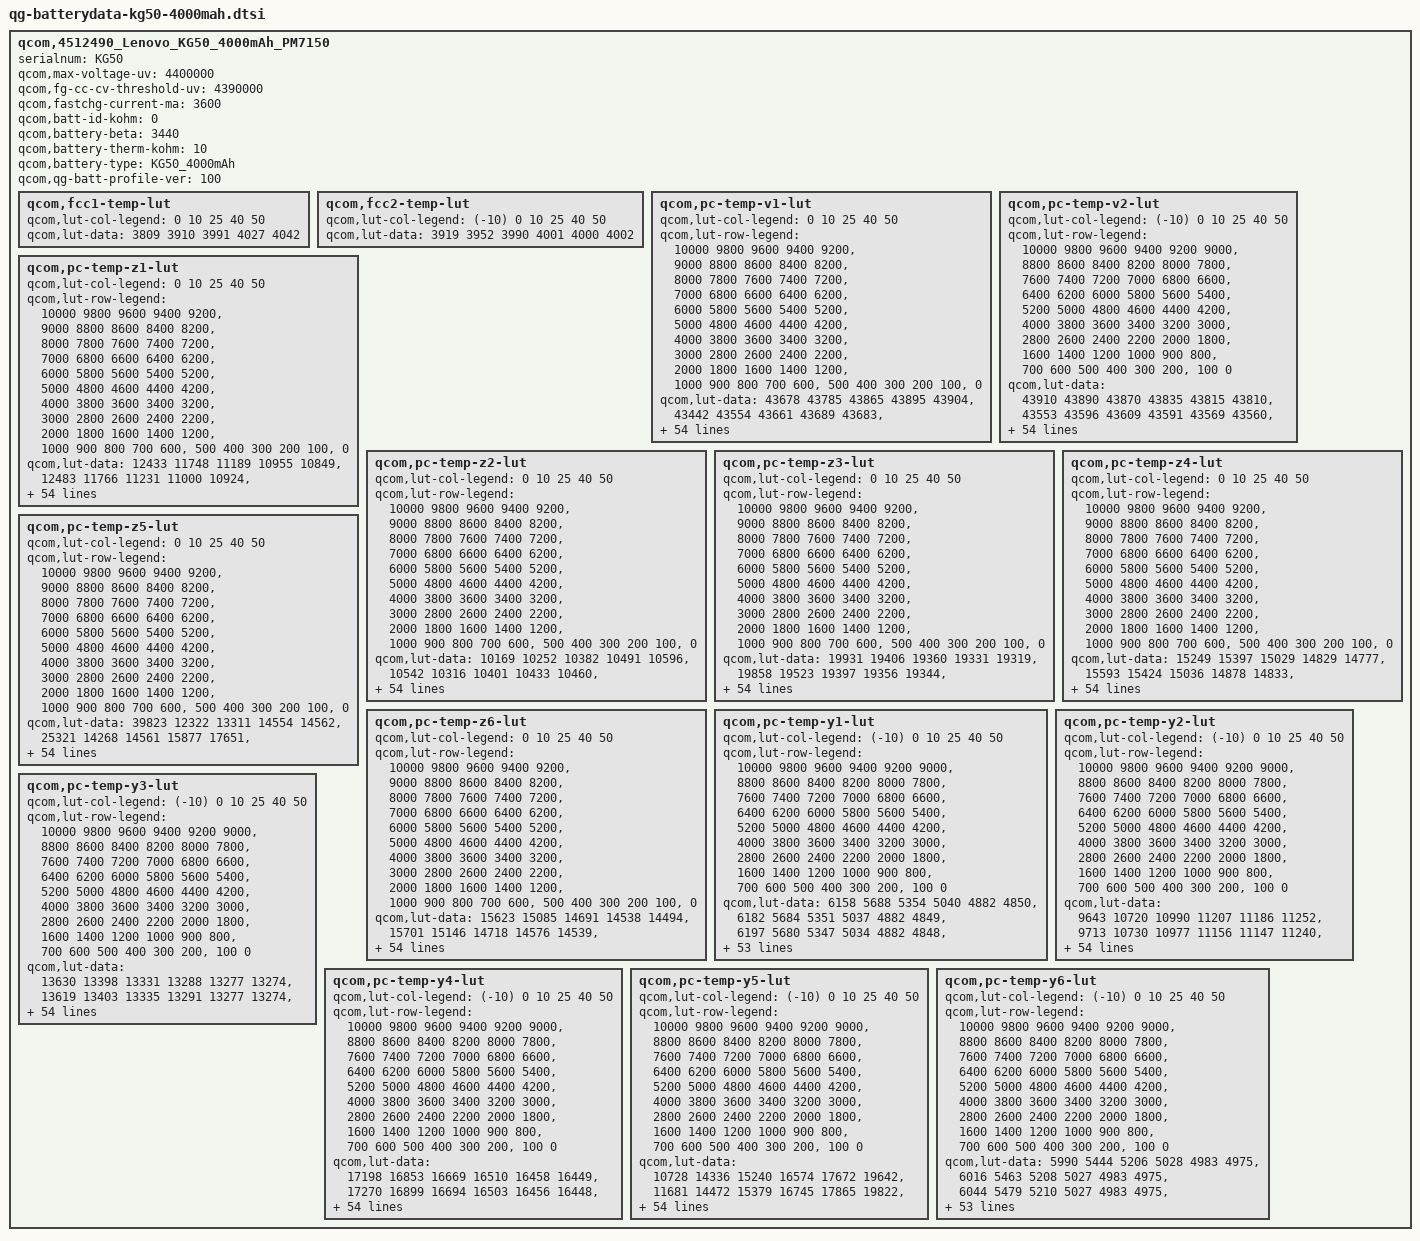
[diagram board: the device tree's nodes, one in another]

qcom,4512490_Lenovo_KG50_4000mAh_PM7150 {
    /* 4512490_Lenovo_KG50_4000mAh_PM7150_averaged_MasterSlave_Mar26th2020 */
    serialnum = "KG50";
    qcom,max-voltage-uv = <4400000>;
    qcom,fg-cc-cv-threshold-uv = <4390000>;
    qcom,fastchg-current-ma = <3600>;
    qcom,batt-id-kohm = <0>;
    qcom,battery-beta = <3440>;
    qcom,battery-therm-kohm = <10>;
    qcom,battery-type = "KG50_4000mAh";
    qcom,qg-batt-profile-ver = <100>;

	qcom,fcc1-temp-lut {
		qcom,lut-col-legend = <0 10 25 40 50>;
		qcom,lut-data = <3809 3910 3991 4027 4042>;
	};

	qcom,fcc2-temp-lut {
		qcom,lut-col-legend = <(-10) 0 10 25 40 50>;
		qcom,lut-data = <3919 3952 3990 4001 4000 4002>;
	};

	qcom,pc-temp-v1-lut {
		qcom,lut-col-legend = <0 10 25 40 50>;
		qcom,lut-row-legend = <10000 9800 9600 9400 9200>,
			<9000 8800 8600 8400 8200>,
			<8000 7800 7600 7400 7200>,
			<7000 6800 6600 6400 6200>,
			<6000 5800 5600 5400 5200>,
			<5000 4800 4600 4400 4200>,
			<4000 3800 3600 3400 3200>,
			<3000 2800 2600 2400 2200>,
			<2000 1800 1600 1400 1200>,
			<1000 900 800 700 600>,
			<500 400 300 200 100>,
			<0>;
		qcom,lut-data = <43678 43785 43865 43895 43904>,
			<43442 43554 43661 43689 43683>,
			<43193 43324 43433 43471 43469>,
			<42948 43096 43204 43249 43252>,
			<42714 42865 42974 43023 43029>,
			<42484 42630 42740 42792 42802>,
			<42256 42394 42506 42561 42574>,
			<42031 42163 42272 42327 42344>,
			<41810 41935 42042 42097 42114>,
			<41592 41712 41813 41867 41883>,
			<41377 41493 41587 41640 41654>,
			<41171 41279 41367 41417 41431>,
			<40973 41072 41153 41198 41211>,
			<40780 40875 40947 40988 41000>,
			<40588 40684 40747 40785 40795>,
			<40399 40494 40554 40590 40599>,
			<40220 40307 40368 40401 40409>,
			<40055 40132 40189 40218 40226>,
			<39898 39976 40025 40045 40051>,
			<39749 39823 39878 39891 39892>,
			<39607 39656 39709 39728 39730>,
			<39460 39481 39463 39513 39525>,
			<39297 39294 39198 39262 39279>,
			<39126 39061 39023 39065 39075>,
			<38962 38838 38900 38925 38924>,
			<38784 38716 38793 38804 38797>,
			<38627 38643 38692 38689 38682>,
			<38536 38578 38600 38585 38579>,
			<38474 38507 38512 38492 38485>,
			<38423 38438 38426 38406 38394>,
			<38376 38376 38352 38328 38311>,
			<38335 38317 38287 38256 38237>,
			<38297 38264 38230 38191 38169>,
			<38261 38218 38178 38130 38104>,
			<38228 38176 38133 38076 38043>,
			<38197 38138 38089 38023 37982>,
			<38168 38106 38046 37970 37918>,
			<38130 38068 38002 37915 37850>,
			<38074 38005 37938 37846 37772>,
			<37999 37910 37846 37754 37678>,
			<37906 37804 37739 37648 37572>,
			<37782 37680 37617 37525 37444>,
			<37637 37538 37478 37384 37300>,
			<37469 37370 37315 37225 37142>,
			<37317 37226 37175 37093 37023>,
			<37212 37132 37086 37013 36949>,
			<37178 37105 37061 36991 36926>,
			<37153 37082 37043 36975 36911>,
			<37120 37057 37022 36955 36892>,
			<37076 37002 36969 36878 36785>,
			<36959 36759 36705 36574 36457>,
			<36592 36311 36268 36122 36001>,
			<36067 35721 35691 35535 35406>,
			<35366 34913 34909 34732 34589>,
			<34267 33618 33708 33487 33312>,
			<30000 30000 30000 30000 30000>;
	};

	qcom,pc-temp-v2-lut {
		qcom,lut-col-legend = <(-10) 0 10 25 40 50>;
		qcom,lut-row-legend = <10000 9800 9600 9400 9200 9000>,
			<8800 8600 8400 8200 8000 7800>,
			<7600 7400 7200 7000 6800 6600>,
			<6400 6200 6000 5800 5600 5400>,
			<5200 5000 4800 4600 4400 4200>,
			<4000 3800 3600 3400 3200 3000>,
			<2800 2600 2400 2200 2000 1800>,
			<1600 1400 1200 1000 900 800>,
			<700 600 500 400 300 200>,
			<100 0>;
		qcom,lut-data = <43910 43890 43870 43835 43815 43810>,
			<43553 43596 43609 43591 43569 43560>,
			<43233 43319 43354 43350 43328 43316>,
			<42956 43059 43109 43114 43091 43079>,
			<42720 42819 42873 42884 42862 42851>,
			<42492 42581 42637 42653 42632 42622>,
			<42258 42338 42398 42417 42398 42389>,
			<42024 42096 42160 42180 42163 42154>,
			<41778 41861 41926 41948 41932 41924>,
			<41505 41636 41696 41720 41703 41695>,
			<41255 41413 41469 41494 41477 41469>,
			<41077 41191 41247 41274 41258 41249>,
			<40935 40970 41029 41056 41042 41032>,
			<40753 40767 40821 40848 40835 40825>,
			<40487 40582 40619 40645 40632 40621>,
			<40195 40396 40424 40449 40436 40426>,
			<39943 40191 40241 40258 40247 40239>,
			<39710 39977 40061 40073 40066 40058>,
			<39489 39760 39859 39896 39894 39887>,
			<39279 39534 39631 39729 39735 39729>,
			<39076 39313 39407 39548 39560 39555>,
			<38864 39109 39198 39316 39331 39329>,
			<38635 38918 39002 39072 39088 39090>,
			<38450 38744 38833 38887 38901 38905>,
			<38327 38583 38685 38738 38751 38755>,
			<38231 38435 38554 38609 38622 38626>,
			<38163 38296 38437 38494 38510 38512>,
			<38109 38165 38331 38393 38410 38410>,
			<38058 38067 38232 38299 38318 38316>,
			<38006 38002 38137 38213 38233 38228>,
			<37954 37950 38049 38134 38154 38149>,
			<37900 37902 37965 38060 38084 38078>,
			<37846 37859 37890 37991 38017 38011>,
			<37788 37814 37834 37926 37949 37938>,
			<37730 37769 37795 37867 37879 37858>,
			<37670 37722 37755 37803 37801 37769>,
			<37606 37674 37710 37732 37708 37662>,
			<37537 37626 37660 37655 37607 37548>,
			<37462 37566 37597 37575 37516 37451>,
			<37377 37488 37519 37493 37432 37366>,
			<37281 37393 37425 37402 37342 37276>,
			<37183 37281 37306 37293 37235 37171>,
			<37085 37146 37166 37167 37113 37049>,
			<36994 37002 37010 37010 36960 36897>,
			<36920 36860 36882 36908 36868 36812>,
			<36848 36758 36802 36867 36835 36781>,
			<36812 36720 36767 36851 36821 36769>,
			<36770 36681 36730 36832 36806 36753>,
			<36715 36636 36677 36794 36772 36703>,
			<36647 36572 36567 36681 36629 36503>,
			<36539 36438 36300 36356 36261 36093>,
			<36325 36127 35803 35847 35739 35549>,
			<35951 35604 35139 35195 35065 34837>,
			<35375 34883 34255 34302 34151 33894>,
			<34487 33798 32912 33056 32824 32377>,
			<33082 32024 29815 30325 30858 29304>;
	};

	qcom,pc-temp-z1-lut {
		qcom,lut-col-legend = <0 10 25 40 50>;
		qcom,lut-row-legend = <10000 9800 9600 9400 9200>,
			<9000 8800 8600 8400 8200>,
			<8000 7800 7600 7400 7200>,
			<7000 6800 6600 6400 6200>,
			<6000 5800 5600 5400 5200>,
			<5000 4800 4600 4400 4200>,
			<4000 3800 3600 3400 3200>,
			<3000 2800 2600 2400 2200>,
			<2000 1800 1600 1400 1200>,
			<1000 900 800 700 600>,
			<500 400 300 200 100>,
			<0>;
		qcom,lut-data = <12433 11748 11189 10955 10849>,
			<12483 11766 11231 11000 10924>,
			<12500 11782 11252 11010 10941>,
			<12501 11796 11252 11013 10948>,
			<12490 11801 11244 11012 10950>,
			<12475 11795 11236 11009 10952>,
			<12463 11782 11230 11008 10952>,
			<12453 11765 11226 11007 10953>,
			<12440 11740 11224 11006 10953>,
			<12422 11723 11222 11004 10952>,
			<12398 11721 11220 11003 10951>,
			<12380 11724 11217 11002 10951>,
			<12370 11724 11214 11002 10951>,
			<12359 11717 11214 11002 10951>,
			<12340 11710 11215 11002 10951>,
			<12316 11705 11216 11003 10951>,
			<12307 11702 11216 11003 10951>,
			<12316 11702 11216 11003 10952>,
			<12333 11712 11217 11004 10953>,
			<12346 11724 11221 11005 10954>,
			<12355 11723 11223 11006 10955>,
			<12360 11716 11224 11007 10955>,
			<12354 11713 11225 11007 10956>,
			<12345 11718 11227 11008 10957>,
			<12342 11726 11230 11010 10958>,
			<12353 11732 11234 11013 10961>,
			<12366 11736 11238 11015 10963>,
			<12365 11738 11243 11018 10965>,
			<12359 11736 11247 11021 10967>,
			<12356 11731 11252 11023 10969>,
			<12368 11731 11256 11026 10971>,
			<12392 11738 11261 11029 10973>,
			<12405 11747 11265 11032 10975>,
			<12403 11753 11270 11036 10977>,
			<12398 11759 11274 11039 10980>,
			<12399 11767 11278 11042 10982>,
			<12409 11782 11284 11046 10985>,
			<12421 11795 11291 11049 10987>,
			<12438 11802 11296 11052 10989>,
			<12456 11807 11301 11055 10991>,
			<12464 11812 11304 11058 10993>,
			<12462 11825 11305 11060 10995>,
			<12469 11831 11305 11061 10997>,
			<12494 11819 11313 11063 10997>,
			<12470 11808 11316 11066 10998>,
			<12506 11837 11320 11067 10999>,
			<12484 11821 11324 11066 10999>,
			<12485 11821 11325 11068 11000>,
			<12504 11820 11333 11069 11001>,
			<12504 11844 11334 11073 11003>,
			<12485 11861 11336 11077 11007>,
			<12505 11874 11349 11082 11011>,
			<12554 11889 11358 11090 11018>,
			<12520 11902 11382 11101 11026>,
			<12520 11902 11382 11101 11026>,
			<12520 11902 11382 11101 11026>;
	};

	qcom,pc-temp-z2-lut {
		qcom,lut-col-legend = <0 10 25 40 50>;
		qcom,lut-row-legend = <10000 9800 9600 9400 9200>,
			<9000 8800 8600 8400 8200>,
			<8000 7800 7600 7400 7200>,
			<7000 6800 6600 6400 6200>,
			<6000 5800 5600 5400 5200>,
			<5000 4800 4600 4400 4200>,
			<4000 3800 3600 3400 3200>,
			<3000 2800 2600 2400 2200>,
			<2000 1800 1600 1400 1200>,
			<1000 900 800 700 600>,
			<500 400 300 200 100>,
			<0>;
		qcom,lut-data = <10169 10252 10382 10491 10596>,
			<10542 10316 10401 10433 10460>,
			<10289 10298 10420 10430 10500>,
			<10114 10263 10411 10428 10511>,
			<10098 10231 10372 10423 10496>,
			<10087 10205 10332 10418 10472>,
			<10079 10182 10299 10408 10435>,
			<10072 10163 10274 10383 10379>,
			<10066 10144 10273 10357 10354>,
			<10059 10134 10288 10332 10351>,
			<10049 10141 10303 10315 10351>,
			<10041 10160 10313 10317 10358>,
			<10033 10189 10322 10327 10389>,
			<10028 10331 10329 10333 10416>,
			<10032 10491 10338 10337 10426>,
			<10044 10477 10347 10344 10434>,
			<10053 10330 10355 10351 10442>,
			<10058 10250 10364 10356 10456>,
			<10064 10263 10375 10365 10474>,
			<10072 10280 10392 10393 10497>,
			<10087 10298 10419 10437 10528>,
			<10104 10318 10505 10517 10604>,
			<10121 10331 10604 10630 10728>,
			<10137 10338 10596 10681 10774>,
			<10150 10343 10485 10671 10772>,
			<10165 10339 10416 10658 10760>,
			<10178 10317 10453 10629 10693>,
			<10179 10301 10508 10534 10536>,
			<10175 10306 10513 10478 10447>,
			<10174 10316 10484 10432 10412>,
			<10175 10323 10458 10393 10395>,
			<10177 10326 10447 10376 10404>,
			<10179 10331 10440 10366 10436>,
			<10185 10340 10443 10370 10475>,
			<10192 10352 10471 10412 10531>,
			<10198 10359 10501 10466 10591>,
			<10204 10362 10521 10517 10648>,
			<10212 10364 10539 10572 10701>,
			<10225 10375 10563 10615 10720>,
			<10238 10394 10596 10652 10724>,
			<10242 10403 10614 10675 10728>,
			<10243 10404 10599 10676 10742>,
			<10247 10405 10584 10672 10757>,
			<10267 10410 10589 10684 10715>,
			<10428 10478 10613 10688 10696>,
			<10447 10496 10600 10668 10731>,
			<10398 10488 10569 10673 10722>,
			<10192 10486 10556 10672 10759>,
			<10085 10560 10553 10694 10837>,
			<10094 10627 10569 10712 10786>,
			<9970 10553 10596 10550 10526>,
			<9988 10495 10509 10475 10471>,
			<9883 10357 10464 10398 10408>,
			<9704 10197 10389 10336 10325>,
			<9704 10197 10389 10336 10325>,
			<9704 10197 10389 10336 10325>;
	};

	qcom,pc-temp-z3-lut {
		qcom,lut-col-legend = <0 10 25 40 50>;
		qcom,lut-row-legend = <10000 9800 9600 9400 9200>,
			<9000 8800 8600 8400 8200>,
			<8000 7800 7600 7400 7200>,
			<7000 6800 6600 6400 6200>,
			<6000 5800 5600 5400 5200>,
			<5000 4800 4600 4400 4200>,
			<4000 3800 3600 3400 3200>,
			<3000 2800 2600 2400 2200>,
			<2000 1800 1600 1400 1200>,
			<1000 900 800 700 600>,
			<500 400 300 200 100>,
			<0>;
		qcom,lut-data = <19931 19406 19360 19331 19319>,
			<19858 19523 19397 19356 19344>,
			<19757 19561 19439 19371 19357>,
			<19748 19576 19456 19384 19364>,
			<19763 19585 19465 19392 19370>,
			<19774 19591 19468 19398 19373>,
			<19775 19594 19466 19397 19373>,
			<19770 19594 19461 19391 19366>,
			<19764 19589 19455 19386 19361>,
			<19761 19583 19446 19380 19360>,
			<19759 19573 19440 19376 19359>,
			<19756 19559 19436 19374 19357>,
			<19747 19553 19431 19373 19355>,
			<19737 19558 19427 19371 19353>,
			<19727 19565 19421 19365 19349>,
			<19717 19560 19417 19360 19344>,
			<19707 19543 19415 19357 19341>,
			<19699 19528 19412 19356 19339>,
			<19692 19520 19408 19354 19337>,
			<19686 19514 19402 19351 19334>,
			<19679 19515 19400 19348 19332>,
			<19675 19521 19413 19351 19333>,
			<19680 19526 19430 19361 19340>,
			<19687 19529 19428 19365 19349>,
			<19690 19532 19405 19364 19366>,
			<19693 19530 19391 19363 19382>,
			<19698 19521 19397 19373 19381>,
			<19695 19515 19409 19389 19376>,
			<19687 19517 19421 19393 19371>,
			<19679 19520 19433 19386 19366>,
			<19673 19522 19438 19378 19361>,
			<19667 19524 19434 19372 19354>,
			<19663 19526 19426 19366 19347>,
			<19659 19525 19420 19361 19341>,
			<19656 19522 19415 19356 19334>,
			<19653 19518 19411 19353 19330>,
			<19650 19515 19407 19350 19330>,
			<19647 19511 19404 19348 19331>,
			<19641 19506 19402 19348 19332>,
			<19633 19502 19400 19349 19334>,
			<19624 19497 19399 19351 19336>,
			<19615 19494 19395 19350 19337>,
			<19605 19489 19392 19349 19339>,
			<19594 19482 19388 19350 19342>,
			<19535 19456 19378 19346 19337>,
			<19506 19444 19369 19331 19320>,
			<19452 19435 19366 19327 19318>,
			<19323 19424 19363 19326 19314>,
			<19290 19388 19361 19322 19304>,
			<19284 19383 19351 19324 19317>,
			<19274 19404 19360 19343 19333>,
			<19294 19345 19355 19347 19333>,
			<19298 19354 19360 19347 19335>,
			<19325 19368 19364 19349 19340>,
			<19325 19368 19364 19349 19340>,
			<19325 19368 19364 19349 19340>;
	};

	qcom,pc-temp-z4-lut {
		qcom,lut-col-legend = <0 10 25 40 50>;
		qcom,lut-row-legend = <10000 9800 9600 9400 9200>,
			<9000 8800 8600 8400 8200>,
			<8000 7800 7600 7400 7200>,
			<7000 6800 6600 6400 6200>,
			<6000 5800 5600 5400 5200>,
			<5000 4800 4600 4400 4200>,
			<4000 3800 3600 3400 3200>,
			<3000 2800 2600 2400 2200>,
			<2000 1800 1600 1400 1200>,
			<1000 900 800 700 600>,
			<500 400 300 200 100>,
			<0>;
		qcom,lut-data = <15249 15397 15029 14829 14777>,
			<15593 15424 15036 14878 14833>,
			<15752 15382 14996 14854 14815>,
			<15714 15240 14948 14827 14791>,
			<15559 15105 14889 14798 14767>,
			<15382 15021 14839 14768 14745>,
			<15265 14955 14803 14745 14729>,
			<15175 14904 14775 14727 14717>,
			<15101 14862 14757 14717 14707>,
			<15037 14830 14745 14712 14701>,
			<14983 14807 14735 14708 14695>,
			<14939 14791 14727 14702 14690>,
			<14902 14775 14721 14695 14685>,
			<14871 14748 14716 14689 14680>,
			<14850 14725 14712 14685 14676>,
			<14833 14726 14708 14681 14672>,
			<14822 14744 14703 14676 14668>,
			<14813 14752 14699 14671 14663>,
			<14805 14746 14696 14667 14658>,
			<14797 14740 14693 14663 14654>,
			<14787 14742 14692 14661 14651>,
			<14782 14752 14733 14687 14670>,
			<14790 14769 14800 14753 14732>,
			<14808 14825 14829 14782 14760>,
			<14828 14891 14844 14780 14740>,
			<14868 14899 14849 14773 14714>,
			<14905 14882 14832 14752 14702>,
			<14908 14861 14799 14719 14694>,
			<14899 14842 14773 14705 14688>,
			<14888 14823 14749 14699 14683>,
			<14877 14808 14735 14694 14679>,
			<14864 14796 14732 14689 14674>,
			<14852 14787 14730 14685 14669>,
			<14841 14782 14729 14684 14667>,
			<14831 14779 14728 14683 14666>,
			<14821 14776 14728 14683 14666>,
			<14811 14772 14728 14684 14668>,
			<14802 14769 14730 14688 14674>,
			<14794 14770 14732 14691 14677>,
			<14787 14771 14736 14695 14678>,
			<14779 14771 14739 14697 14678>,
			<14770 14756 14732 14694 14677>,
			<14758 14739 14721 14690 14676>,
			<14739 14726 14714 14687 14675>,
			<14704 14694 14692 14676 14667>,
			<14705 14673 14672 14664 14654>,
			<14756 14669 14663 14656 14645>,
			<14893 14667 14652 14641 14632>,
			<14922 14696 14642 14630 14625>,
			<14917 14696 14647 14633 14629>,
			<14924 14684 14662 14643 14639>,
			<14919 14758 14669 14643 14644>,
			<14931 14757 14665 14646 14645>,
			<14935 14757 14661 14645 14644>,
			<14935 14757 14661 14645 14644>,
			<14935 14757 14661 14645 14644>;
	};

	qcom,pc-temp-z5-lut {
		qcom,lut-col-legend = <0 10 25 40 50>;
		qcom,lut-row-legend = <10000 9800 9600 9400 9200>,
			<9000 8800 8600 8400 8200>,
			<8000 7800 7600 7400 7200>,
			<7000 6800 6600 6400 6200>,
			<6000 5800 5600 5400 5200>,
			<5000 4800 4600 4400 4200>,
			<4000 3800 3600 3400 3200>,
			<3000 2800 2600 2400 2200>,
			<2000 1800 1600 1400 1200>,
			<1000 900 800 700 600>,
			<500 400 300 200 100>,
			<0>;
		qcom,lut-data = <39823 12322 13311 14554 14562>,
			<25321 14268 14561 15877 17651>,
			<15542 15168 16305 17182 19105>,
			<14257 15653 17481 18488 20203>,
			<14695 16165 18337 19678 21425>,
			<15182 16913 19072 20740 22413>,
			<15606 17721 19745 21323 22654>,
			<16029 18457 20217 21780 22532>,
			<16533 19240 20480 21863 22544>,
			<17243 20004 21012 21580 23003>,
			<18081 20609 21405 21435 23746>,
			<18840 21156 21771 21964 24532>,
			<19520 21912 22033 23066 25485>,
			<20258 24913 21969 23491 25934>,
			<21287 28108 22125 23148 25578>,
			<22410 27976 22518 22802 25091>,
			<23085 25625 23108 23181 25293>,
			<23519 24398 23815 24502 26554>,
			<23981 24739 24381 25539 27895>,
			<24728 25306 24830 26116 29221>,
			<26086 27071 25681 26685 30205>,
			<27966 31440 31985 27660 30060>,
			<32258 34092 40246 28810 28807>,
			<37668 34088 39053 28614 27461>,
			<40115 33411 26859 23178 25500>,
			<41967 31784 19247 18260 23915>,
			<43412 27358 19340 19570 23955>,
			<42099 24497 19706 22835 24577>,
			<38225 24796 20926 24244 25287>,
			<35003 25489 24785 24689 26333>,
			<33296 26444 27831 25127 27139>,
			<32005 28589 28943 25806 27152>,
			<31581 30769 29715 26689 27049>,
			<31641 32284 30438 27611 27095>,
			<31870 33593 31163 28821 27854>,
			<32402 34095 31495 29549 28474>,
			<33383 34203 31302 29315 28599>,
			<34317 34203 30869 28675 28978>,
			<35449 34079 30235 28072 29172>,
			<36500 33864 29035 27318 29230>,
			<36353 33684 28080 26686 29330>,
			<34598 33549 27663 26529 30264>,
			<34305 33431 27372 26657 31720>,
			<35810 33017 26651 26697 32321>,
			<34341 33864 27099 25939 29139>,
			<26226 33350 27374 22221 21415>,
			<19895 29277 27555 22046 22546>,
			<12092 25398 28332 25104 24937>,
			<11547 18915 30284 28511 24363>,
			<11463 19306 24944 27688 32577>,
			<11353 19941 22357 27281 30602>,
			<11656 13433 19330 27141 26491>,
			<11535 13774 19535 24530 24652>,
			<11894 14586 19854 23428 23923>,
			<11894 14586 19854 23428 23923>,
			<11894 14586 19854 23428 23923>;
	};

	qcom,pc-temp-z6-lut {
		qcom,lut-col-legend = <0 10 25 40 50>;
		qcom,lut-row-legend = <10000 9800 9600 9400 9200>,
			<9000 8800 8600 8400 8200>,
			<8000 7800 7600 7400 7200>,
			<7000 6800 6600 6400 6200>,
			<6000 5800 5600 5400 5200>,
			<5000 4800 4600 4400 4200>,
			<4000 3800 3600 3400 3200>,
			<3000 2800 2600 2400 2200>,
			<2000 1800 1600 1400 1200>,
			<1000 900 800 700 600>,
			<500 400 300 200 100>,
			<0>;
		qcom,lut-data = <15623 15085 14691 14538 14494>,
			<15701 15146 14718 14576 14539>,
			<15688 15137 14723 14577 14541>,
			<15651 15072 14717 14577 14539>,
			<15570 15007 14693 14570 14534>,
			<15477 14964 14669 14558 14526>,
			<15409 14928 14651 14548 14518>,
			<15352 14898 14635 14537 14510>,
			<15303 14871 14622 14529 14503>,
			<15263 14849 14612 14524 14499>,
			<15228 14829 14604 14519 14496>,
			<15196 14813 14598 14515 14492>,
			<15167 14802 14593 14511 14489>,
			<15142 14793 14588 14507 14486>,
			<15123 14786 14583 14502 14481>,
			<15107 14782 14579 14498 14477>,
			<15097 14779 14575 14494 14473>,
			<15089 14776 14572 14491 14470>,
			<15083 14769 14569 14488 14467>,
			<15078 14764 14565 14485 14463>,
			<15073 14766 14564 14482 14461>,
			<15071 14773 14590 14496 14470>,
			<15077 14785 14629 14531 14501>,
			<15091 14813 14636 14543 14517>,
			<15104 14844 14634 14542 14517>,
			<15124 14847 14630 14541 14516>,
			<15144 14836 14625 14539 14513>,
			<15145 14825 14620 14534 14507>,
			<15138 14819 14616 14529 14502>,
			<15131 14814 14613 14523 14497>,
			<15125 14811 14610 14518 14492>,
			<15119 14808 14607 14513 14487>,
			<15114 14807 14603 14508 14481>,
			<15109 14805 14601 14505 14477>,
			<15106 14804 14598 14502 14473>,
			<15104 14803 14597 14500 14471>,
			<15103 14803 14597 14500 14472>,
			<15102 14802 14597 14501 14475>,
			<15102 14803 14597 14502 14477>,
			<15102 14805 14600 14505 14478>,
			<15101 14805 14601 14507 14480>,
			<15100 14801 14598 14505 14480>,
			<15098 14795 14592 14503 14481>,
			<15094 14791 14589 14503 14482>,
			<15063 14771 14576 14497 14476>,
			<15052 14759 14564 14484 14462>,
			<15046 14753 14559 14478 14457>,
			<15040 14748 14553 14471 14449>,
			<15038 14745 14548 14464 14440>,
			<15039 14747 14548 14467 14449>,
			<15046 14759 14561 14482 14464>,
			<15062 14767 14565 14486 14467>,
			<15081 14780 14569 14489 14471>,
			<15110 14802 14576 14493 14475>,
			<15110 14802 14576 14493 14475>,
			<15110 14802 14576 14493 14475>;
	};

	qcom,pc-temp-y1-lut {
		qcom,lut-col-legend = <(-10) 0 10 25 40 50>;
		qcom,lut-row-legend = <10000 9800 9600 9400 9200 9000>,
			<8800 8600 8400 8200 8000 7800>,
			<7600 7400 7200 7000 6800 6600>,
			<6400 6200 6000 5800 5600 5400>,
			<5200 5000 4800 4600 4400 4200>,
			<4000 3800 3600 3400 3200 3000>,
			<2800 2600 2400 2200 2000 1800>,
			<1600 1400 1200 1000 900 800>,
			<700 600 500 400 300 200>,
			<100 0>;
		qcom,lut-data = <6158 5688 5354 5040 4882 4850>,
			<6182 5684 5351 5037 4882 4849>,
			<6197 5680 5347 5034 4882 4848>,
			<6205 5678 5343 5031 4881 4846>,
			<6208 5676 5339 5028 4880 4845>,
			<6208 5676 5336 5025 4879 4843>,
			<6204 5677 5331 5021 4878 4842>,
			<6196 5678 5327 5018 4876 4841>,
			<6195 5678 5325 5015 4875 4841>,
			<6200 5676 5322 5012 4873 4840>,
			<6205 5674 5321 5010 4872 4840>,
			<6206 5673 5324 5008 4872 4840>,
			<6208 5673 5327 5006 4871 4841>,
			<6210 5674 5327 5005 4871 4841>,
			<6212 5678 5322 5004 4871 4840>,
			<6214 5683 5319 5004 4871 4840>,
			<6214 5687 5319 5003 4871 4840>,
			<6213 5691 5319 5003 4870 4840>,
			<6213 5691 5320 5003 4870 4840>,
			<6215 5689 5320 5005 4871 4840>,
			<6218 5687 5321 5007 4871 4840>,
			<6218 5688 5322 5008 4872 4840>,
			<6215 5693 5325 5010 4872 4840>,
			<6211 5694 5327 5011 4872 4840>,
			<6204 5689 5327 5012 4873 4842>,
			<6197 5684 5328 5013 4874 4843>,
			<6200 5686 5328 5015 4875 4843>,
			<6220 5691 5330 5018 4877 4843>,
			<6229 5693 5333 5021 4878 4844>,
			<6216 5692 5339 5024 4880 4844>,
			<6199 5691 5343 5027 4881 4845>,
			<6199 5694 5341 5030 4883 4847>,
			<6212 5702 5337 5034 4884 4849>,
			<6219 5704 5337 5037 4886 4850>,
			<6214 5699 5341 5039 4888 4851>,
			<6203 5692 5343 5042 4890 4851>,
			<6192 5686 5344 5043 4891 4852>,
			<6179 5680 5345 5045 4891 4854>,
			<6170 5678 5347 5047 4892 4855>,
			<6181 5678 5353 5050 4894 4855>,
			<6199 5679 5357 5053 4896 4856>,
			<6200 5681 5355 5054 4897 4857>,
			<6181 5685 5353 5056 4898 4858>,
			<6177 5691 5357 5060 4898 4859>,
			<6187 5692 5364 5064 4901 4860>,
			<6190 5693 5363 5067 4903 4861>,
			<6203 5709 5369 5066 4904 4862>,
			<6212 5714 5371 5068 4904 4862>,
			<6223 5718 5372 5070 4903 4862>,
			<6210 5720 5377 5071 4904 4863>,
			<6221 5717 5370 5071 4905 4864>,
			<6240 5719 5378 5081 4910 4868>,
			<6288 5737 5385 5091 4915 4872>,
			<6396 5772 5409 5104 4923 4878>,
			<6396 5772 5409 5104 4923 4878>,
			<6396 5772 5409 5104 4923 4878>;
	};

	qcom,pc-temp-y2-lut {
		qcom,lut-col-legend = <(-10) 0 10 25 40 50>;
		qcom,lut-row-legend = <10000 9800 9600 9400 9200 9000>,
			<8800 8600 8400 8200 8000 7800>,
			<7600 7400 7200 7000 6800 6600>,
			<6400 6200 6000 5800 5600 5400>,
			<5200 5000 4800 4600 4400 4200>,
			<4000 3800 3600 3400 3200 3000>,
			<2800 2600 2400 2200 2000 1800>,
			<1600 1400 1200 1000 900 800>,
			<700 600 500 400 300 200>,
			<100 0>;
		qcom,lut-data = <9643 10720 10990 11207 11186 11252>,
			<9713 10730 10977 11156 11147 11240>,
			<9923 10739 10960 11102 11107 11221>,
			<10133 10745 10941 11052 11070 11195>,
			<10310 10747 10920 11010 11036 11164>,
			<10420 10746 10899 10980 11008 11128>,
			<10468 10737 10872 10961 10982 11078>,
			<10497 10726 10843 10947 10961 11028>,
			<10511 10722 10828 10932 10956 11010>,
			<10562 10726 10819 10914 10959 11001>,
			<10603 10735 10815 10904 10961 10998>,
			<10613 10766 10822 10904 10952 11003>,
			<10639 10823 10840 10905 10939 11011>,
			<10648 10865 10868 10909 10933 11019>,
			<10492 10895 10921 10927 10943 11025>,
			<10297 10924 10980 10953 10956 11025>,
			<10261 10967 11046 10998 10959 11017>,
			<10243 11019 11106 11063 10962 11014>,
			<10202 11033 11119 11141 11010 11040>,
			<9954 11001 11117 11248 11184 11118>,
			<9707 10957 11113 11303 11290 11178>,
			<9682 10932 11103 11276 11265 11200>,
			<9678 10912 11089 11234 11227 11228>,
			<9674 10889 11085 11223 11224 11264>,
			<9671 10849 11093 11225 11248 11309>,
			<9669 10806 11100 11230 11275 11336>,
			<9667 10784 11099 11245 11295 11359>,
			<9665 10767 11092 11270 11315 11391>,
			<9664 10751 11081 11298 11338 11418>,
			<9662 10597 11063 11334 11373 11468>,
			<9661 10374 11049 11351 11399 11491>,
			<9661 10243 11040 11346 11414 11498>,
			<9660 10049 11033 11338 11431 11515>,
			<9660 9907 11024 11338 11438 11539>,
			<9659 9811 11009 11350 11439 11579>,
			<9659 9743 10988 11353 11431 11600>,
			<9659 9710 10956 11318 11412 11574>,
			<9659 9688 10910 11275 11389 11534>,
			<9659 9677 10857 11268 11383 11526>,
			<9659 9671 10792 11273 11388 11535>,
			<9659 9668 10714 11276 11388 11539>,
			<9659 9665 10585 11241 11363 11508>,
			<9658 9663 10401 11186 11353 11460>,
			<9658 9661 10253 11151 11376 11421>,
			<9658 9659 10147 11130 11344 11377>,
			<9658 9658 10110 11108 11242 11271>,
			<9658 9658 9958 11122 11241 11208>,
			<9657 9657 9908 11137 11205 11220>,
			<9657 9657 9838 11143 11257 11245>,
			<9656 9656 9783 11126 11226 11203>,
			<9656 9656 9716 11064 11134 11134>,
			<9654 9655 9680 10988 11034 11058>,
			<9652 9654 9663 10934 10969 10931>,
			<9650 9652 9657 10881 10855 10720>,
			<9650 9652 9657 10881 10855 10720>,
			<9650 9652 9657 10881 10855 10720>;
	};

	qcom,pc-temp-y3-lut {
		qcom,lut-col-legend = <(-10) 0 10 25 40 50>;
		qcom,lut-row-legend = <10000 9800 9600 9400 9200 9000>,
			<8800 8600 8400 8200 8000 7800>,
			<7600 7400 7200 7000 6800 6600>,
			<6400 6200 6000 5800 5600 5400>,
			<5200 5000 4800 4600 4400 4200>,
			<4000 3800 3600 3400 3200 3000>,
			<2800 2600 2400 2200 2000 1800>,
			<1600 1400 1200 1000 900 800>,
			<700 600 500 400 300 200>,
			<100 0>;
		qcom,lut-data = <13630 13398 13331 13288 13277 13274>,
			<13619 13403 13335 13291 13277 13274>,
			<13609 13408 13338 13293 13278 13275>,
			<13600 13413 13341 13295 13279 13275>,
			<13594 13418 13344 13296 13279 13275>,
			<13592 13421 13346 13296 13280 13275>,
			<13594 13424 13348 13296 13280 13276>,
			<13598 13426 13349 13295 13281 13276>,
			<13595 13428 13351 13295 13281 13276>,
			<13556 13434 13352 13296 13281 13277>,
			<13517 13438 13353 13297 13281 13277>,
			<13511 13431 13353 13298 13282 13277>,
			<13510 13414 13352 13300 13284 13278>,
			<13513 13405 13352 13301 13284 13278>,
			<13524 13402 13348 13303 13286 13280>,
			<13535 13399 13346 13304 13286 13280>,
			<13530 13398 13345 13304 13287 13281>,
			<13515 13397 13344 13304 13288 13282>,
			<13509 13394 13342 13304 13289 13283>,
			<13519 13384 13338 13305 13291 13285>,
			<13531 13373 13333 13305 13292 13286>,
			<13532 13367 13328 13302 13288 13283>,
			<13521 13361 13324 13296 13282 13279>,
			<13513 13357 13321 13293 13279 13276>,
			<13509 13352 13319 13291 13277 13274>,
			<13515 13349 13317 13289 13276 13273>,
			<13538 13345 13316 13289 13276 13273>,
			<13583 13340 13316 13288 13277 13273>,
			<13636 13336 13315 13288 13277 13273>,
			<13694 13337 13314 13288 13277 13273>,
			<13758 13342 13312 13288 13277 13274>,
			<13822 13348 13311 13288 13277 13274>,
			<13887 13357 13310 13288 13277 13273>,
			<13950 13368 13310 13288 13277 13273>,
			<14009 13388 13313 13288 13277 13274>,
			<14066 13417 13316 13288 13277 13274>,
			<14119 13451 13319 13287 13277 13273>,
			<14168 13495 13323 13287 13276 13272>,
			<14213 13543 13326 13287 13276 13272>,
			<14253 13590 13330 13286 13276 13273>,
			<14291 13642 13333 13286 13276 13274>,
			<14326 13703 13337 13287 13277 13275>,
			<14356 13774 13340 13288 13277 13275>,
			<14386 13858 13346 13288 13275 13273>,
			<14428 13965 13358 13289 13275 13273>,
			<14500 14091 13364 13290 13276 13276>,
			<14530 14105 13362 13291 13280 13278>,
			<14568 14183 13379 13296 13284 13280>,
			<14647 14301 13406 13300 13286 13281>,
			<14784 14429 13436 13301 13284 13279>,
			<14995 14553 13476 13298 13282 13278>,
			<15367 14704 13551 13300 13283 13280>,
			<16555 15048 13759 13306 13287 13284>,
			<20873 16420 14307 13315 13292 13289>,
			<20873 16420 14307 13315 13292 13289>,
			<20873 16420 14307 13315 13292 13289>;
	};

	qcom,pc-temp-y4-lut {
		qcom,lut-col-legend = <(-10) 0 10 25 40 50>;
		qcom,lut-row-legend = <10000 9800 9600 9400 9200 9000>,
			<8800 8600 8400 8200 8000 7800>,
			<7600 7400 7200 7000 6800 6600>,
			<6400 6200 6000 5800 5600 5400>,
			<5200 5000 4800 4600 4400 4200>,
			<4000 3800 3600 3400 3200 3000>,
			<2800 2600 2400 2200 2000 1800>,
			<1600 1400 1200 1000 900 800>,
			<700 600 500 400 300 200>,
			<100 0>;
		qcom,lut-data = <17198 16853 16669 16510 16458 16449>,
			<17270 16899 16694 16503 16456 16448>,
			<17359 16957 16711 16499 16454 16447>,
			<17446 17014 16721 16496 16453 16447>,
			<17514 17059 16727 16494 16453 16446>,
			<17544 17078 16728 16494 16453 16446>,
			<17534 17072 16723 16495 16453 16447>,
			<17514 17061 16714 16498 16455 16447>,
			<17509 17052 16708 16500 16457 16448>,
			<17532 17044 16705 16504 16459 16449>,
			<17563 17039 16703 16507 16462 16451>,
			<17597 17059 16707 16512 16465 16453>,
			<17640 17106 16716 16517 16468 16456>,
			<17648 17138 16732 16524 16472 16459>,
			<17542 17165 16768 16534 16477 16463>,
			<17398 17179 16805 16547 16484 16466>,
			<17309 17160 16834 16567 16493 16472>,
			<17241 17104 16856 16592 16505 16480>,
			<17174 17047 16853 16621 16524 16494>,
			<17106 16989 16802 16656 16557 16520>,
			<17033 16930 16743 16673 16576 16534>,
			<16943 16875 16693 16623 16548 16515>,
			<16830 16822 16647 16540 16499 16481>,
			<16768 16773 16619 16508 16476 16465>,
			<16760 16725 16601 16492 16463 16455>,
			<16760 16679 16589 16486 16458 16451>,
			<16763 16630 16584 16488 16459 16451>,
			<16767 16580 16581 16491 16461 16452>,
			<16771 16562 16576 16496 16464 16454>,
			<16778 16575 16566 16501 16470 16459>,
			<16787 16598 16555 16508 16477 16464>,
			<16796 16623 16538 16515 16487 16474>,
			<16806 16657 16520 16523 16498 16484>,
			<16815 16687 16518 16527 16502 16487>,
			<16824 16712 16533 16529 16503 16488>,
			<16832 16735 16554 16529 16503 16487>,
			<16838 16753 16577 16517 16491 16477>,
			<16844 16769 16603 16499 16473 16463>,
			<16847 16778 16624 16491 16467 16460>,
			<16842 16780 16644 16488 16464 16460>,
			<16827 16780 16656 16486 16464 16460>,
			<16815 16774 16662 16491 16465 16464>,
			<16809 16762 16664 16497 16466 16466>,
			<16808 16756 16663 16492 16455 16450>,
			<16821 16750 16662 16492 16449 16442>,
			<16850 16752 16652 16494 16458 16449>,
			<16852 16755 16664 16503 16467 16470>,
			<16852 16766 16700 16521 16496 16528>,
			<16874 16812 16753 16557 16560 16575>,
			<16912 16868 16817 16584 16543 16518>,
			<16941 16907 16839 16540 16474 16468>,
			<16946 16909 16841 16535 16472 16470>,
			<17039 16896 16926 16570 16489 16488>,
			<18026 17124 17095 16649 16564 16602>,
			<18026 17124 17095 16649 16564 16602>,
			<18026 17124 17095 16649 16564 16602>;
	};

	qcom,pc-temp-y5-lut {
		qcom,lut-col-legend = <(-10) 0 10 25 40 50>;
		qcom,lut-row-legend = <10000 9800 9600 9400 9200 9000>,
			<8800 8600 8400 8200 8000 7800>,
			<7600 7400 7200 7000 6800 6600>,
			<6400 6200 6000 5800 5600 5400>,
			<5200 5000 4800 4600 4400 4200>,
			<4000 3800 3600 3400 3200 3000>,
			<2800 2600 2400 2200 2000 1800>,
			<1600 1400 1200 1000 900 800>,
			<700 600 500 400 300 200>,
			<100 0>;
		qcom,lut-data = <10728 14336 15240 16574 17672 19642>,
			<11681 14472 15379 16745 17865 19822>,
			<12607 14623 15543 16808 17925 19840>,
			<13472 14773 15704 16788 17880 19730>,
			<14239 14910 15834 16708 17759 19525>,
			<14872 15018 15903 16592 17588 19256>,
			<15441 15105 15920 16003 17308 18839>,
			<15918 15181 15920 15124 16905 18301>,
			<15948 15263 15885 14806 16426 17838>,
			<14995 15533 15731 14716 15778 17423>,
			<14118 15722 15512 14657 15303 17005>,
			<14649 15256 15167 14574 15293 16523>,
			<16225 14350 14741 14505 15521 16050>,
			<17226 14133 14447 14466 15574 15764>,
			<17633 14815 14202 14405 15421 15785>,
			<17774 15790 14089 14319 15280 15903>,
			<17729 16897 14762 14176 15013 15809>,
			<17712 18110 16127 14033 14655 15546>,
			<17777 18610 17225 14297 14695 15453>,
			<18287 18752 18232 15878 15164 15604>,
			<18952 18876 18913 17533 15834 15967>,
			<18700 19154 19253 18897 17123 17568>,
			<16610 19575 19497 20000 18510 19486>,
			<14864 19945 19594 20099 18641 19748>,
			<13387 20462 19636 19592 17999 19433>,
			<11853 20951 19695 19031 17491 19031>,
			<11706 20756 19916 18536 17479 18546>,
			<11920 19035 20307 18122 17606 17988>,
			<12157 17567 20686 18061 17601 17520>,
			<12308 15776 21184 18290 17196 17035>,
			<12463 14000 21499 18459 16867 16835>,
			<12603 13416 20972 18623 16784 16709>,
			<12742 13078 19840 18964 16815 16512>,
			<12834 13028 19482 19552 17234 16753>,
			<12906 13178 19503 20738 18248 17849>,
			<13033 13443 19513 21657 19127 18636>,
			<13155 13879 19309 22109 19687 18778>,
			<13269 14661 18830 22394 20129 18863>,
			<13344 15184 18381 22188 20394 19301>,
			<13338 15332 17902 21022 20584 20344>,
			<13275 15412 17472 19875 20664 21333>,
			<13149 15333 17031 19049 20547 22678>,
			<12735 14812 16497 18595 20301 23200>,
			<12368 13944 16039 18548 20237 22630>,
			<12349 13242 15777 18501 19471 20632>,
			<12408 13102 15536 18146 16667 19260>,
			<12498 12991 14456 17559 18164 19865>,
			<12620 13119 14284 18140 19341 18451>,
			<12662 13132 14359 18294 17688 15838>,
			<12908 13396 14512 18022 16888 16727>,
			<13396 13750 14379 18644 19476 19169>,
			<13259 13474 13618 19655 20227 19692>,
			<12285 12798 12819 20175 21297 21708>,
			<10393 11926 12374 20799 22530 22526>,
			<10393 11926 12374 20799 22530 22526>,
			<10393 11926 12374 20799 22530 22526>;
	};

	qcom,pc-temp-y6-lut {
		qcom,lut-col-legend = <(-10) 0 10 25 40 50>;
		qcom,lut-row-legend = <10000 9800 9600 9400 9200 9000>,
			<8800 8600 8400 8200 8000 7800>,
			<7600 7400 7200 7000 6800 6600>,
			<6400 6200 6000 5800 5600 5400>,
			<5200 5000 4800 4600 4400 4200>,
			<4000 3800 3600 3400 3200 3000>,
			<2800 2600 2400 2200 2000 1800>,
			<1600 1400 1200 1000 900 800>,
			<700 600 500 400 300 200>,
			<100 0>;
		qcom,lut-data = <5990 5444 5206 5028 4983 4975>,
			<6016 5463 5208 5027 4983 4975>,
			<6044 5479 5210 5027 4983 4975>,
			<6070 5491 5210 5026 4983 4975>,
			<6088 5499 5210 5026 4984 4975>,
			<6097 5503 5210 5026 4984 4975>,
			<6094 5499 5207 5025 4984 4976>,
			<6087 5493 5201 5025 4985 4976>,
			<6077 5489 5198 5025 4986 4976>,
			<6056 5487 5196 5027 4986 4977>,
			<6039 5486 5194 5028 4987 4978>,
			<6046 5485 5194 5030 4989 4979>,
			<6063 5485 5195 5032 4991 4980>,
			<6069 5487 5197 5035 4993 4981>,
			<6038 5492 5204 5039 4995 4983>,
			<5996 5496 5211 5044 4997 4985>,
			<5970 5491 5218 5049 5000 4987>,
			<5948 5476 5223 5056 5004 4990>,
			<5929 5459 5221 5064 5010 4995>,
			<5915 5438 5204 5074 5021 5003>,
			<5901 5416 5184 5080 5027 5008>,
			<5883 5399 5166 5063 5016 5000>,
			<5858 5385 5151 5035 4998 4987>,
			<5844 5373 5142 5024 4989 4980>,
			<5852 5363 5136 5018 4984 4976>,
			<5872 5354 5133 5016 4982 4974>,
			<5898 5347 5133 5016 4982 4974>,
			<5944 5340 5133 5017 4983 4975>,
			<5996 5338 5132 5018 4984 4975>,
			<6048 5349 5131 5020 4986 4976>,
			<6103 5373 5129 5023 4988 4978>,
			<6157 5400 5127 5026 4991 4981>,
			<6212 5438 5124 5028 4994 4984>,
			<6264 5479 5124 5030 4995 4985>,
			<6312 5526 5134 5031 4996 4985>,
			<6357 5576 5148 5032 4996 4985>,
			<6398 5629 5163 5029 4993 4982>,
			<6437 5684 5182 5023 4987 4977>,
			<6472 5739 5200 5022 4985 4977>,
			<6501 5795 5220 5021 4985 4977>,
			<6526 5852 5240 5021 4985 4978>,
			<6549 5912 5260 5024 4986 4980>,
			<6570 5977 5281 5027 4987 4981>,
			<6595 6052 5306 5027 4982 4975>,
			<6634 6145 5339 5029 4981 4972>,
			<6699 6249 5345 5031 4985 4977>,
			<6730 6264 5355 5035 4990 4985>,
			<6764 6331 5399 5044 5001 5003>,
			<6834 6437 5457 5058 5021 5017>,
			<6955 6553 5523 5066 5015 4999>,
			<7132 6663 5587 5052 4994 4985>,
			<7433 6786 5688 5054 4994 4987>,
			<8409 7050 5937 5072 5003 4996>,
			<11905 8165 6446 5106 5029 5033>,
			<11905 8165 6446 5106 5029 5033>,
			<11905 8165 6446 5106 5029 5033>;
	};

};
